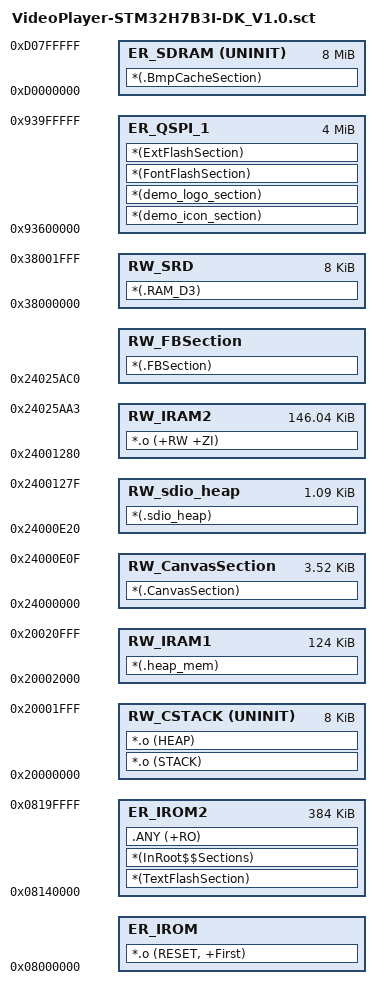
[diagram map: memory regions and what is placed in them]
; *************************************************************
; *** Scatter-Loading Description File generated by uVision ***
; *************************************************************

LR_IROM1 0x08000000   {    ; load region size_region
	ER_IROM 0x08000000  {  ; load address = execution address
		*.o (RESET, +First)
	   	}
}	
LR_IROM2 0x08140000 0x60000  {    ; load region size_region
	ER_IROM2 0x08140000 0x60000  {  ; load address = execution address
		*(TextFlashSection)
		*(InRoot$$Sections)
	    .ANY (+RO)
	   	}
	RW_CSTACK 0x20000000 UNINIT 0x00002000  {  ; RW data
		*.o (STACK)
		*.o (HEAP)
	}
	RW_IRAM1 0x20002000 0x0001F000  {  ; RW data
		*(.heap_mem)
		}
	
	RW_CanvasSection  0x24000000 0xe10{
	*(.CanvasSection)
	}
	
	RW_sdio_heap  0x24000e20 0x460{
	*(.sdio_heap)
	}
	RW_IRAM2  0x24001280 0x24824{
		
		*.o (+RW +ZI)
		}
	RW_FBSection  0x24025ac0 {
		*(.FBSection)
		}
    RW_SRD 0x38000000 0x2000    { ; RW data
        *(.RAM_D3)
    }
	
	ER_SDRAM 0xD0000000 UNINIT 0x800000{ 
		*(.BmpCacheSection)
	} 
}
LR_QSPI 0x93600000  {
	ER_QSPI_1  0x93600000 0x400000 { 
	*(demo_icon_section)
	*(demo_logo_section)
	*(FontFlashSection)	
	*(ExtFlashSection)
	}
}
